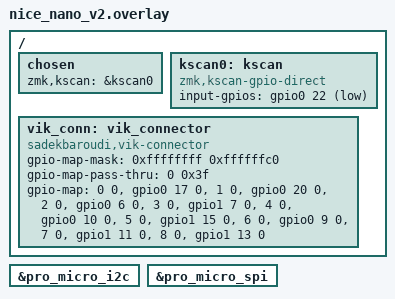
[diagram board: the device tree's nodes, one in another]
/ {
    chosen {
        zmk,kscan = &kscan0;
    };

	kscan0: kscan {
	compatible = "zmk,kscan-gpio-direct";

	input-gpios
		= <&gpio0 22 (GPIO_ACTIVE_LOW | GPIO_PULL_UP)>
		;
};


};

/ {
	vik_conn: vik_connector {
		compatible = "sadekbaroudi,vik-connector";
		#gpio-cells = <2>;
		gpio-map-mask = <0xffffffff 0xffffffc0>;
		gpio-map-pass-thru = <0 0x3f>;
		gpio-map
			= <0 0 &gpio0  17 0>    /* vik SDA */
			, <1 0 &gpio0  20 0>    /* vik SCL */
			, <2 0 &gpio0  6 0>     /* vik RGB Data */
			, <3 0 &gpio1  7 0>     /* vik AD_1 */
			, <4 0 &gpio0  10 0>    /* vik MOSI */
			, <5 0 &gpio1  15 0>    /* vik AD_2 */
			, <6 0 &gpio0  9 0>     /* vik CS */
			, <7 0 &gpio1  11 0>    /* vik MISO */
			, <8 0 &gpio1  13 0>    /* vik SCLK */
			;
	};
};

vik_i2c: &pro_micro_i2c {}; // i2c0
vik_spi: &pro_micro_spi {}; // spi1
